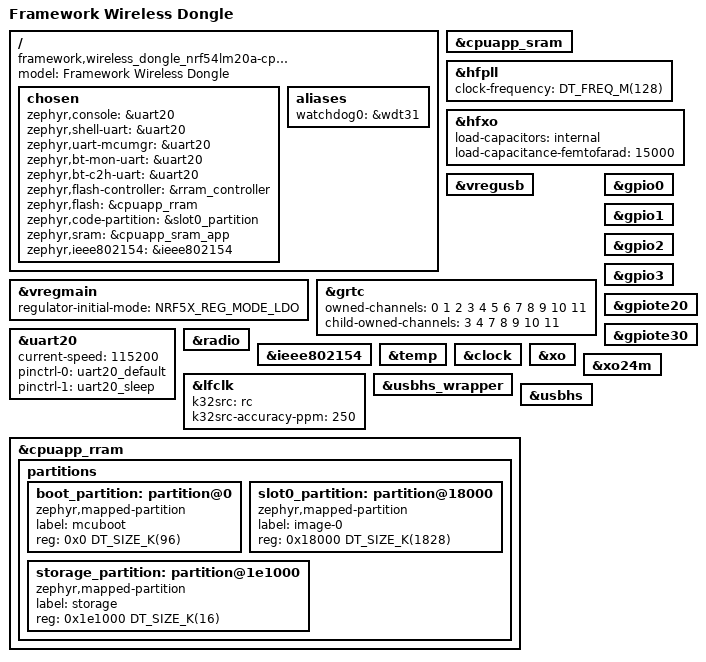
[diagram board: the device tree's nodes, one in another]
/*
 * Copyright (c) 2026 Framework Computer Inc
 *
 * SPDX-License-Identifier: Apache-2.0
 */

/dts-v1/;

#include <nordic/nrf54lm20a_cpuapp.dtsi>
#include "framework_wireless_dongle-pinctrl.dtsi"

/ {
	compatible = "framework,wireless_dongle_nrf54lm20a-cpuapp";
	model = "Framework Wireless Dongle";

	chosen {
		zephyr,console = &uart20;
		zephyr,shell-uart = &uart20;
		zephyr,uart-mcumgr = &uart20;
		zephyr,bt-mon-uart = &uart20;
		zephyr,bt-c2h-uart = &uart20;
		zephyr,flash-controller = &rram_controller;
		zephyr,flash = &cpuapp_rram;
		zephyr,code-partition = &slot0_partition;
		zephyr,sram = &cpuapp_sram_app;
		zephyr,ieee802154 = &ieee802154;
	};

	aliases {
		watchdog0 = &wdt31;
	};
};

&cpuapp_sram {
	status = "okay";
};

&hfpll {
	clock-frequency = <DT_FREQ_M(128)>;
};

&hfxo {
	load-capacitors = "internal";
	load-capacitance-femtofarad = <15000>;
};

/* No DCDC inductor is fitted, VREGMAIN runs in LDO mode. */
&vregmain {
	status = "okay";
	regulator-initial-mode = <NRF5X_REG_MODE_LDO>;
};

&vregusb {
	status = "okay";
};

&grtc {
	owned-channels = <0 1 2 3 4 5 6 7 8 9 10 11>;
	/* Channels 7-11 reserved for Zero Latency IRQs, 3-4 for FLPR */
	child-owned-channels = <3 4 7 8 9 10 11>;
	status = "okay";
};

/* Debug UART on test pads */
&uart20 {
	status = "okay";
	current-speed = <115200>;
	pinctrl-0 = <&uart20_default>;
	pinctrl-1 = <&uart20_sleep>;
	pinctrl-names = "default", "sleep";
};

&gpio0 {
	status = "okay";
};

&gpio1 {
	status = "okay";
};

&gpio2 {
	status = "okay";
};

&gpio3 {
	status = "okay";
};

&gpiote20 {
	status = "okay";
};

&gpiote30 {
	status = "okay";
};

&radio {
	status = "okay";
};

&ieee802154 {
	status = "okay";
};

&temp {
	status = "okay";
};

&clock {
	status = "okay";
};

&xo {
	status = "okay";
};

/* No 32.768 kHz crystal is fitted, the LFCLK runs from the internal RC oscillator. */
&lfclk {
	status = "okay";
	k32src = "rc";
	k32src-accuracy-ppm = <250>;
};

&xo24m {
	status = "okay";
};

&usbhs_wrapper {
	status = "okay";
};

zephyr_udc0: &usbhs {
	status = "okay";
};

/*
 * Flash layout matching the factory MCUboot bootloader: 96 kB bootloader
 * with USB serial recovery, a single application slot and 16 kB of settings
 * storage. The last 96 kB of RRAM are reserved for the FLPR core.
 */
&cpuapp_rram {
	partitions {
		ranges;
		#address-cells = <1>;
		#size-cells = <1>;

		boot_partition: partition@0 {
			compatible = "zephyr,mapped-partition";
			label = "mcuboot";
			reg = <0x0 DT_SIZE_K(96)>;
		};

		slot0_partition: partition@18000 {
			compatible = "zephyr,mapped-partition";
			label = "image-0";
			reg = <0x18000 DT_SIZE_K(1828)>;
		};

		storage_partition: partition@1e1000 {
			compatible = "zephyr,mapped-partition";
			label = "storage";
			reg = <0x1e1000 DT_SIZE_K(16)>;
		};
	};
};
